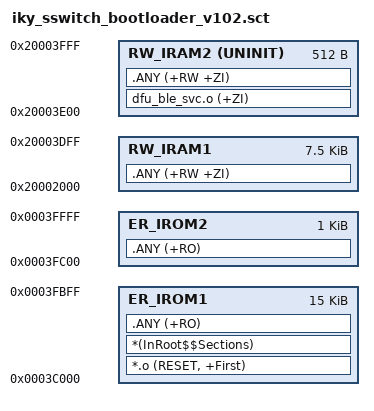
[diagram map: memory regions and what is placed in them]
; *************************************************************
; *** Scatter-Loading Description File generated by uVision ***
; *************************************************************

LR_IROM1 0x0003C000 0x00003C00  {    ; load region size_region
  ER_IROM1 0x0003C000 0x00003C00  {  ; load address = execution address
   *.o (RESET, +First)
   *(InRoot$$Sections)
   .ANY (+RO)
  }
  RW_IRAM1 0x20002000 0x00001E00  {  ; RW data
   .ANY (+RW +ZI)
  }
  RW_IRAM2 0x20003E00 UNINIT 0x00000200  {
    dfu_ble_svc.o (+ZI)
   .ANY (+RW +ZI)
  }
}

LR_IROM2 0x0003FC00 0x00000400  {
  ER_IROM2 0x0003FC00 0x00000400  {  ; load address = execution address
   .ANY (+RO)
  }
}
